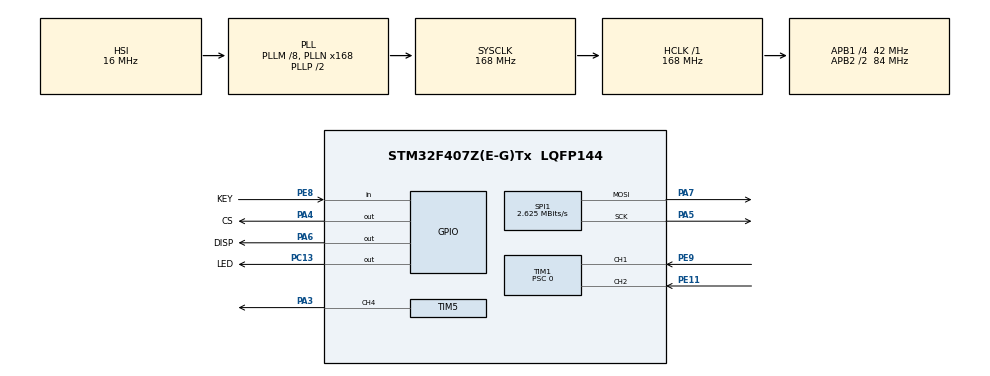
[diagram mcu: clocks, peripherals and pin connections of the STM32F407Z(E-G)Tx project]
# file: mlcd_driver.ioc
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FREERTOS.Tasks01=defaultTask,24,512,StartDefaultTask,Default,NULL,Dynamic,NULL,NULL;GUITask,32,1024,StartGUITask,Default,NULL,Dynamic,NULL,NULL
FREERTOS.configENABLE_FPU=1
FREERTOS.configTOTAL_HEAP_SIZE=32768
Mcu.Family=STM32F4
Mcu.Name=STM32F407Z(E-G)Tx
Mcu.Package=LQFP144
NVIC.PriorityGroup=NVIC_PRIORITYGROUP_4
NVIC.TIM6_DAC_IRQn=true\:15\:0\:false\:false\:true\:false\:false\:true\:true
NVIC.TimeBase=TIM6_DAC_IRQn
NVIC.TimeBaseIP=TIM6
PA13.Mode=Serial_Wire
PA13.Signal=SYS_JTMS-SWDIO
PA14.Mode=Serial_Wire
PA14.Signal=SYS_JTCK-SWCLK
PA3.Signal=S_TIM5_CH4
PA4.GPIO_Label=CS
PA4.GPIO_PuPd=GPIO_PULLUP
PA4.PinState=GPIO_PIN_SET
PA4.Signal=GPIO_Output
PA5.Mode=TX_Only_Simplex_Unidirect_Master
PA5.Signal=SPI1_SCK
PA6.GPIO_Label=DISP
PA6.GPIO_PuPd=GPIO_PULLDOWN
PA6.Signal=GPIO_Output
PA7.Mode=TX_Only_Simplex_Unidirect_Master
PA7.Signal=SPI1_MOSI
PC13-ANTI_TAMP.GPIO_Label=LED
PC13-ANTI_TAMP.GPIO_PuPd=GPIO_PULLUP
PC13-ANTI_TAMP.Signal=GPIO_Output
PE11.Signal=S_TIM1_CH2
PE8.GPIO_Label=KEY
PE8.GPIO_PuPd=GPIO_PULLUP
PE8.Signal=GPIO_Input
PE9.Signal=S_TIM1_CH1
ProjectManager.HeapSize=0x200
ProjectManager.StackSize=0x400
ProjectManager.TargetToolchain=CMake
RCC.48MHZClocksFreq_Value=84000000
RCC.AHBFreq_Value=168000000
RCC.APB1CLKDivider=RCC_HCLK_DIV4
RCC.APB1Freq_Value=42000000
RCC.APB1TimFreq_Value=84000000
RCC.APB2CLKDivider=RCC_HCLK_DIV2
RCC.APB2Freq_Value=84000000
RCC.APB2TimFreq_Value=168000000
RCC.CortexFreq_Value=168000000
RCC.HCLKFreq_Value=168000000
RCC.HSE_VALUE=25000000
RCC.HSI_VALUE=16000000
RCC.LSE_VALUE=32768
RCC.PLLM=8
RCC.PLLN=168
RCC.SYSCLKFreq_VALUE=168000000
RCC.SYSCLKSource=RCC_SYSCLKSOURCE_PLLCLK
RCC.VCOOutputFreq_Value=336000000
SH.S_TIM1_CH1.0=TIM1_CH1,Encoder_Interface
SH.S_TIM1_CH2.0=TIM1_CH2,Encoder_Interface
SH.S_TIM5_CH4.0=TIM5_CH4,PWM Generation4 CH4
SPI1.BaudRatePrescaler=SPI_BAUDRATEPRESCALER_32
SPI1.CalculateBaudRate=2.625 MBits/s
SPI1.Direction=SPI_DIRECTION_2LINES
SPI1.FirstBit=SPI_FIRSTBIT_LSB
SPI1.Mode=SPI_MODE_MASTER
SPI1.VirtualType=VM_MASTER
TIM1.AutoReloadPreload=TIM_AUTORELOAD_PRELOAD_ENABLE
TIM1.EncoderMode=TIM_ENCODERMODE_TI12
TIM1.IC1Filter=10
TIM1.IC1Polarity=TIM_ICPOLARITY_FALLING
TIM1.IC2Filter=10
TIM1.IC2Polarity=TIM_ICPOLARITY_RISING
TIM1.Prescaler=0
TIM5.AutoReloadPreload=TIM_AUTORELOAD_PRELOAD_ENABLE
TIM5.Channel-PWM\ Generation4\ CH4=TIM_CHANNEL_4
TIM5.Period=199
TIM5.Prescaler=8399
TIM5.Pulse-PWM\ Generation4\ CH4=100
VP_FREERTOS_VS_CMSIS_V2.Mode=CMSIS_V2
VP_SYS_VS_tim6.Mode=TIM6
board=custom

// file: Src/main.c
/* USER CODE BEGIN Header */
/**
  ******************************************************************************
  * @file           : main.c
  * @brief          : Main program body
  ******************************************************************************
  * @attention
  *
  * Copyright (c) 2025 STMicroelectronics.
  * All rights reserved.
  *
  * This software is licensed under terms that can be found in the LICENSE file
  * in the root directory of this software component.
  * If no LICENSE file comes with this software, it is provided AS-IS.
  *
  ******************************************************************************
  */
/* USER CODE END Header */
#include "main.h"
#include "cmsis_os.h"
#include "spi.h"
#include "tim.h"
#include "gpio.h"

/* USER CODE BEGIN Includes */
#include <stdlib.h> // for rand, srand
#include <stdio.h>
#include "animation.h"
#include "encoder.h"
#include "menu.h"

/* USER CODE END Includes */

void SystemClock_Config(void);
void MX_FREERTOS_Init(void);

int main(void)
{

  /* MCU Configuration--------------------------------------------------------*/

  /* Reset of all peripherals, Initializes the Flash interface and the Systick. */
  HAL_Init();

  /* Configure the system clock */
  SystemClock_Config();

  /* Initialize all configured peripherals */
  MX_GPIO_Init();
  MX_SPI1_Init();
  MX_TIM5_Init();
  MX_TIM1_Init();
  /* USER CODE BEGIN 2 */
  MLCD_Init();
  Encoder_Init();

  // 动态构建菜单
  Setup_Menus();

  // Menu_Init 已经在 Setup_Menus 内部调用了 (或者我们应该保持分离)
  // 在 menu.c 的 Setup_Menus 实现中，最后调用了 Menu_Init(page_main)。
  // 所以这里 main.c 只需要调用 Setup_Menus 即可。

  /* USER CODE END 2 */

  /* Init scheduler */
  osKernelInitialize();  /* Call init function for freertos objects (in cmsis_os2.c) */
  MX_FREERTOS_Init();

  /* Start scheduler */
  osKernelStart();

  /* We should never get here as control is now taken by the scheduler */

  /* Infinite loop */
  while (1)
  {

    /* USER CODE BEGIN 3 */
    // Menu_Loop(); // Moved to FreeRTOS Task
  }
  /* USER CODE END 3 */
}

void SystemClock_Config(void)
{
  RCC_OscInitTypeDef RCC_OscInitStruct = {0};
  RCC_ClkInitTypeDef RCC_ClkInitStruct = {0};

  /** Configure the main internal regulator output voltage
  */
  __HAL_RCC_PWR_CLK_ENABLE();
  __HAL_PWR_VOLTAGESCALING_CONFIG(PWR_REGULATOR_VOLTAGE_SCALE1);

  /** Initializes the RCC Oscillators according to the specified parameters
  * in the RCC_OscInitTypeDef structure.
  */
  RCC_OscInitStruct.OscillatorType = RCC_OSCILLATORTYPE_HSI;
  RCC_OscInitStruct.HSIState = RCC_HSI_ON;
  RCC_OscInitStruct.HSICalibrationValue = RCC_HSICALIBRATION_DEFAULT;
  RCC_OscInitStruct.PLL.PLLState = RCC_PLL_ON;
  RCC_OscInitStruct.PLL.PLLSource = RCC_PLLSOURCE_HSI;
  RCC_OscInitStruct.PLL.PLLM = 8;
  RCC_OscInitStruct.PLL.PLLN = 168;
  RCC_OscInitStruct.PLL.PLLP = RCC_PLLP_DIV2;
  RCC_OscInitStruct.PLL.PLLQ = 4;
  if (HAL_RCC_OscConfig(&RCC_OscInitStruct) != HAL_OK)
  {
    Error_Handler();
  }

  /** Initializes the CPU, AHB and APB buses clocks
  */
  RCC_ClkInitStruct.ClockType = RCC_CLOCKTYPE_HCLK|RCC_CLOCKTYPE_SYSCLK
                              |RCC_CLOCKTYPE_PCLK1|RCC_CLOCKTYPE_PCLK2;
  RCC_ClkInitStruct.SYSCLKSource = RCC_SYSCLKSOURCE_PLLCLK;
  RCC_ClkInitStruct.AHBCLKDivider = RCC_SYSCLK_DIV1;
  RCC_ClkInitStruct.APB1CLKDivider = RCC_HCLK_DIV4;
  RCC_ClkInitStruct.APB2CLKDivider = RCC_HCLK_DIV2;

  if (HAL_RCC_ClockConfig(&RCC_ClkInitStruct, FLASH_LATENCY_5) != HAL_OK)
  {
    Error_Handler();
  }
}

void HAL_TIM_PeriodElapsedCallback(TIM_HandleTypeDef *htim)
{
  if (htim->Instance == TIM6)
  {
    HAL_IncTick();
  }
}

void Error_Handler(void)
{
  __disable_irq();
  while (1)
  {
  }
}

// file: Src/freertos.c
/* USER CODE BEGIN Header */
/**
  ******************************************************************************
  * File Name          : freertos.c
  * Description        : Code for freertos applications
  ******************************************************************************
  * @attention
  *
  * Copyright (c) 2026 STMicroelectronics.
  * All rights reserved.
  *
  * This software is licensed under terms that can be found in the LICENSE file
  * in the root directory of this software component.
  * If no LICENSE file comes with this software, it is provided AS-IS.
  *
  ******************************************************************************
  */
/* USER CODE END Header */

#include "FreeRTOS.h"
#include "task.h"
#include "main.h"
#include "cmsis_os.h"

/* USER CODE BEGIN Includes */
#include "menu.h"
/* USER CODE END Includes */

/* Definitions for defaultTask */
osThreadId_t defaultTaskHandle;
const osThreadAttr_t defaultTask_attributes = {
  .name = "defaultTask",
  .stack_size = 512 * 4,
  .priority = (osPriority_t) osPriorityNormal,
};
/* Definitions for GUITask */
osThreadId_t GUITaskHandle;
const osThreadAttr_t GUITask_attributes = {
  .name = "GUITask",
  .stack_size = 1024 * 4,
  .priority = (osPriority_t) osPriorityAboveNormal,
};

void StartDefaultTask(void *argument);
void StartGUITask(void *argument);

void MX_FREERTOS_Init(void); /* (MISRA C 2004 rule 8.1) */

void MX_FREERTOS_Init(void) {

  /* Create the thread(s) */
  /* creation of defaultTask */
  defaultTaskHandle = osThreadNew(StartDefaultTask, NULL, &defaultTask_attributes);

  /* creation of GUITask */
  GUITaskHandle = osThreadNew(StartGUITask, NULL, &GUITask_attributes);

}

void StartDefaultTask(void *argument)
{
  for(;;)
  {
    osDelay(1);
  }
}

void StartGUITask(void *argument)
{
  /* USER CODE BEGIN StartGUITask */
  /* Infinite loop */
  for(;;)
  {
    Menu_Loop();
    osDelay(1);
  }
  /* USER CODE END StartGUITask */
}
